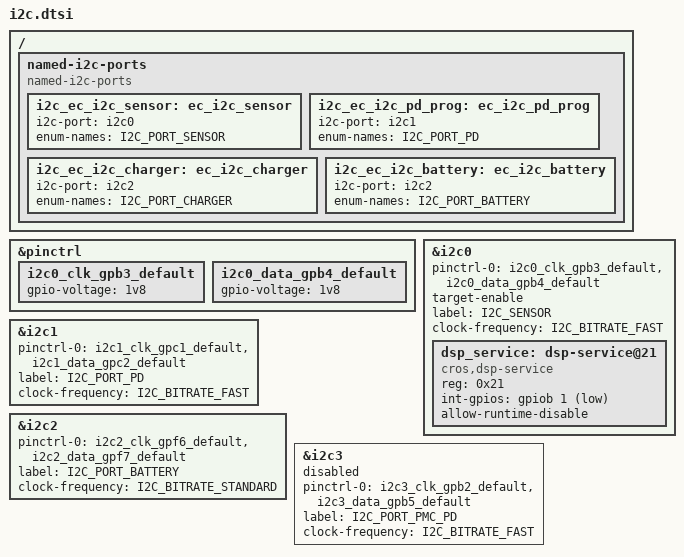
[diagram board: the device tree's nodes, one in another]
/* Copyright 2025 The ChromiumOS Authors
 * Use of this source code is governed by a BSD-style license that can be
 * found in the LICENSE file.
 */

/{

	named-i2c-ports {
		compatible = "named-i2c-ports";

		i2c_ec_i2c_sensor: ec_i2c_sensor {
			i2c-port = <&i2c0>;
			enum-names = "I2C_PORT_SENSOR";
		};
		i2c_ec_i2c_pd_prog: ec_i2c_pd_prog {
			i2c-port = <&i2c1>;
			enum-names = "I2C_PORT_PD";
		};
		i2c_ec_i2c_charger: ec_i2c_charger {
			i2c-port = <&i2c2>;
			enum-names = "I2C_PORT_CHARGER";
		};
		i2c_ec_i2c_battery: ec_i2c_battery {
			i2c-port = <&i2c2>;
			enum-names = "I2C_PORT_BATTERY";
		};
		i2c_i2c_ec_pmc_pd: i2c_ec_pmc_pd {
			i2c-port = <&i2c3>;
			enum-names = "I2C_PORT_PMC_PD";
		};
	};
};

&pinctrl {
	i2c0_clk_gpb3_default: i2c0_clk_gpb3_default {
		gpio-voltage = "1v8";
	};
	i2c0_data_gpb4_default: i2c0_data_gpb4_default {
		gpio-voltage = "1v8";
	};
};

&i2c0 {
	pinctrl-0 = <&i2c0_clk_gpb3_default
		     &i2c0_data_gpb4_default>;
	pinctrl-names = "default";
	target-enable;

	label = "I2C_SENSOR";
	clock-frequency = <I2C_BITRATE_FAST>;
	dsp_service: dsp-service@21 {
		compatible = "cros,dsp-service";
		reg = <0x21>;
		int-gpios = <&gpiob 1 (GPIO_ACTIVE_LOW)>;
		allow-runtime-disable;
	};
};

&i2c1 {
	pinctrl-0 = <&i2c1_clk_gpc1_default
		     &i2c1_data_gpc2_default>;
	pinctrl-names = "default";

	label = "I2C_PORT_PD";
	clock-frequency = <I2C_BITRATE_FAST>;
};

&i2c2 {
	pinctrl-0 = <&i2c2_clk_gpf6_default
		     &i2c2_data_gpf7_default>;
	pinctrl-names = "default";

	label = "I2C_PORT_CHARGER";
	label = "I2C_PORT_BATTERY";
	clock-frequency = <I2C_BITRATE_STANDARD>;
};

&i2c3 {
	pinctrl-0 = <&i2c3_clk_gpb2_default
		     &i2c3_data_gpb5_default>;
	pinctrl-names = "default";

	label = "I2C_PORT_PMC_PD";
	clock-frequency = <I2C_BITRATE_FAST>;
};

&i2c0 {
	status = "okay";
};

&i2c1 {
	status = "okay";
};

&i2c2 {
	status = "okay";
};

&i2c3 {
	status = "disabled";
};
/delete-node/ &i2c_i2c_ec_pmc_pd;
